AUTOSAR XML (schema 00046)
package /ECUAbstractionSWC
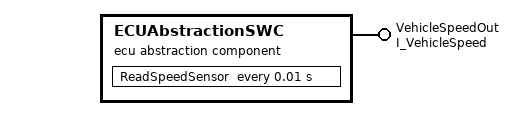
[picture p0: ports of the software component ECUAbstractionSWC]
  ecu abstraction sw component type ECUAbstractionSWC
    provide port VehicleSpeedOut: provided-interface=I_VehicleSpeed
    behavior ECUAbstractionInternalBehavior
      timing event SpeedSensorReadingEvent: start-on-event=ReadSpeedSensor, period=0.01
      runnable ReadSpeedSensor: symbol=ReadSpeedSensor_Function
        data-send-points:
          access VehicleSpeedVariableAccess: accessed-variable=VehicleSpeedOut.VehicleSpeed
